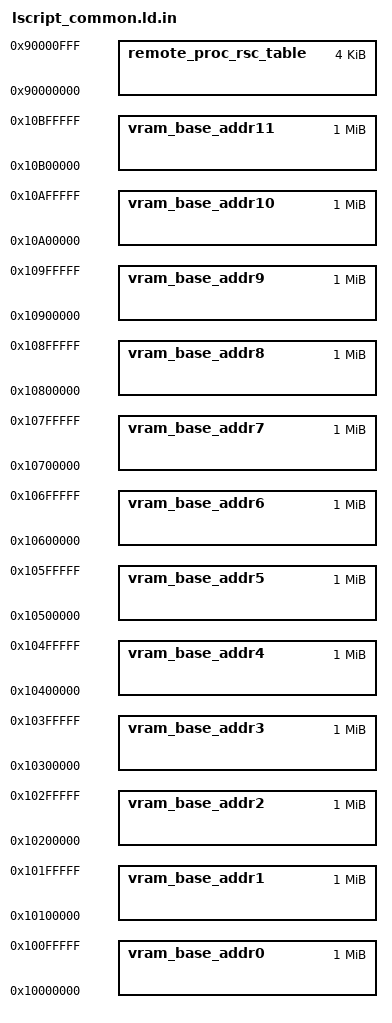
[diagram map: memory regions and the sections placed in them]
MEMORY
{
   vram_base_addr0 : ORIGIN = 0x10000000, LENGTH = 0x100000
   vram_base_addr1 : ORIGIN = 0x10100000, LENGTH = 0x100000
   vram_base_addr2 : ORIGIN = 0x10200000, LENGTH = 0x100000
   vram_base_addr3 : ORIGIN = 0x10300000, LENGTH = 0x100000
   vram_base_addr4 : ORIGIN = 0x10400000, LENGTH = 0x100000
   vram_base_addr5 : ORIGIN = 0x10500000, LENGTH = 0x100000
   vram_base_addr6 : ORIGIN = 0x10600000, LENGTH = 0x100000
   vram_base_addr7 : ORIGIN = 0x10700000, LENGTH = 0x100000
   vram_base_addr8 : ORIGIN = 0x10800000, LENGTH = 0x100000
   vram_base_addr9 : ORIGIN = 0x10900000, LENGTH = 0x100000
   vram_base_addr10 : ORIGIN = 0x10a00000, LENGTH = 0x100000
   vram_base_addr11 : ORIGIN = 0x10b00000, LENGTH = 0x100000
   remote_proc_rsc_table : ORIGIN = 0x90000000, LENGTH = 0x1000
}

REGION_ALIAS("vram_base_addr", @VRAM_SELECTION@)

ENTRY(_Reset)
